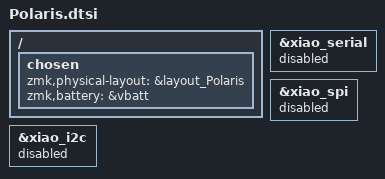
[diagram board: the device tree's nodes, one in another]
#include "Polaris_pins.dtsi"
#include <behaviors/rgbled_widget.dtsi>

#include "Polaris_layout.dtsi"
#include "Polaris_modules.dtsi"
#include "Polaris_hardware.dtsi"

/ {
	chosen {
		zmk,physical-layout = &layout_Polaris;
		zmk,battery = &vbatt;
		// zephyr,boot-mode = &boot_mode0;
	};

	// bootloader_trigger: bootloader_trigger {
	// 	compatible = "zmk,cdc-acm-bootloader-trigger";
	// 	cdc-port = <&snippet_zmk_usb_logging_uart>;
	// };
};

/*
 * The ZMK-qualified XIAO board supplies connector defaults that overlap with
 * Polaris matrix and interchangeable-module pins. Keep them disabled here;
 * a shield or module overlay must explicitly enable only the controller it
 * owns (for example i2c1 for the left OLED or i2c0/spi0 for a module).
 */
&xiao_serial {
	status = "disabled";
};

&xiao_spi {
	status = "disabled";
};

&xiao_i2c {
	status = "disabled";
};

// &gpregret1 {
// 	status = "okay";

// 	boot_mode0: boot_mode@0 {
// 		compatible = "zephyr,retention";
// 		status = "okay";
// 		reg = <0x0 0x1>;
// 	};
// };

// &zephyr_udc0 {
// 	snippet_bootloader_trigger_uart: snippet_bootloader_trigger_uart {
// 		compatible = "zephyr,cdc-acm-uart";
// 	};
// };
